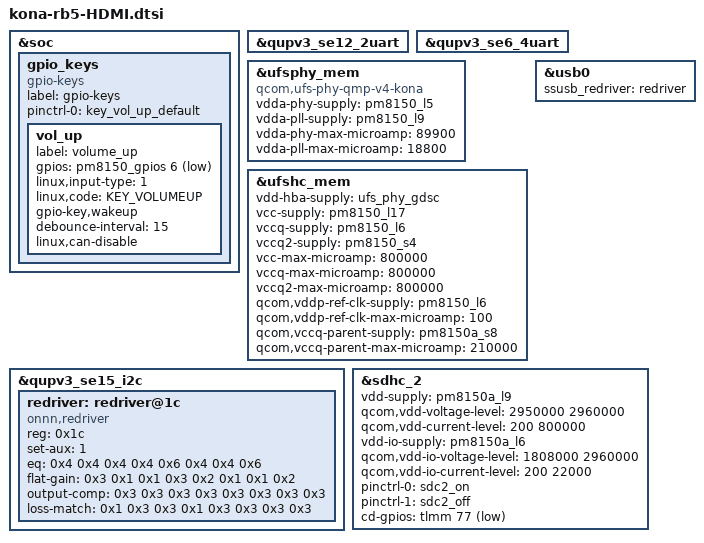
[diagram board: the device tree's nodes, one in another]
#include <dt-bindings/gpio/gpio.h>
#include <dt-bindings/input/input.h>

&soc {
	gpio_keys {
		compatible = "gpio-keys";
		label = "gpio-keys";

		pinctrl-names = "default";
		pinctrl-0 = <&key_vol_up_default>;

		vol_up {
			label = "volume_up";
			gpios = <&pm8150_gpios 6 GPIO_ACTIVE_LOW>;
			linux,input-type = <1>;
			linux,code = <KEY_VOLUMEUP>;
			gpio-key,wakeup;
			debounce-interval = <15>;
			linux,can-disable;
		};
	};
};

&qupv3_se12_2uart {
		status = "ok";
};

&qupv3_se6_4uart {
		status = "ok";
};

&ufsphy_mem {
		compatible = "qcom,ufs-phy-qmp-v4-kona";
		vdda-phy-supply = <&pm8150_l5>;
		vdda-pll-supply = <&pm8150_l9>;
		vdda-phy-max-microamp = <89900>;
		vdda-pll-max-microamp = <18800>;
		status = "ok";
};

&ufshc_mem {
		vdd-hba-supply = <&ufs_phy_gdsc>;
		vcc-supply = <&pm8150_l17>;
		vccq-supply = <&pm8150_l6>;
		vccq2-supply = <&pm8150_s4>;
		vcc-max-microamp = <800000>;
		vccq-max-microamp = <800000>;
		vccq2-max-microamp = <800000>;

		qcom,vddp-ref-clk-supply = <&pm8150_l6>;
		qcom,vddp-ref-clk-max-microamp = <100>;
		qcom,vccq-parent-supply = <&pm8150a_s8>;
		qcom,vccq-parent-max-microamp = <210000>;
		status = "ok";
};

&qupv3_se15_i2c {
	#address-cells = <1>;
	#size-cells = <0>;
	status = "ok";
	redriver: redriver@1c {
		compatible = "onnn,redriver";
		reg = <0x1c>;
		set-aux = <1>;

		eq = /bits/ 8 <
				/* Parameters for USB */
				0x4 0x4 0x4 0x4
				/* Parameters for DP */
				0x6 0x4 0x4 0x6>;
		flat-gain = /bits/ 8 <
				/* Parameters for USB */
				0x3 0x1 0x1 0x3
				/* Parameters for DP */
				0x2 0x1 0x1 0x2>;
		output-comp = /bits/ 8 <
				/* Parameters for USB */
				0x3 0x3 0x3 0x3
				/* Parameters for DP */
				0x3 0x3 0x3 0x3>;
		loss-match = /bits/ 8 <
				/* Parameters for USB */
				0x1 0x3 0x3 0x1
				/* Parameters for DP */
				0x3 0x3 0x3 0x3>;
	};

};

&usb0 {
	ssusb_redriver = <&redriver>;
};

&sdhc_2 {
		vdd-supply = <&pm8150a_l9>;
		qcom,vdd-voltage-level = <2950000 2960000>;
		qcom,vdd-current-level = <200 800000>;

		vdd-io-supply = <&pm8150a_l6>;
		qcom,vdd-io-voltage-level = <1808000 2960000>;
		qcom,vdd-io-current-level = <200 22000>;

		pinctrl-names = "default", "sleep";
		pinctrl-0 = <&sdc2_on>;
		pinctrl-1 = <&sdc2_off>;

		cd-gpios = <&tlmm 77 GPIO_ACTIVE_LOW>;

		status = "ok";
};
